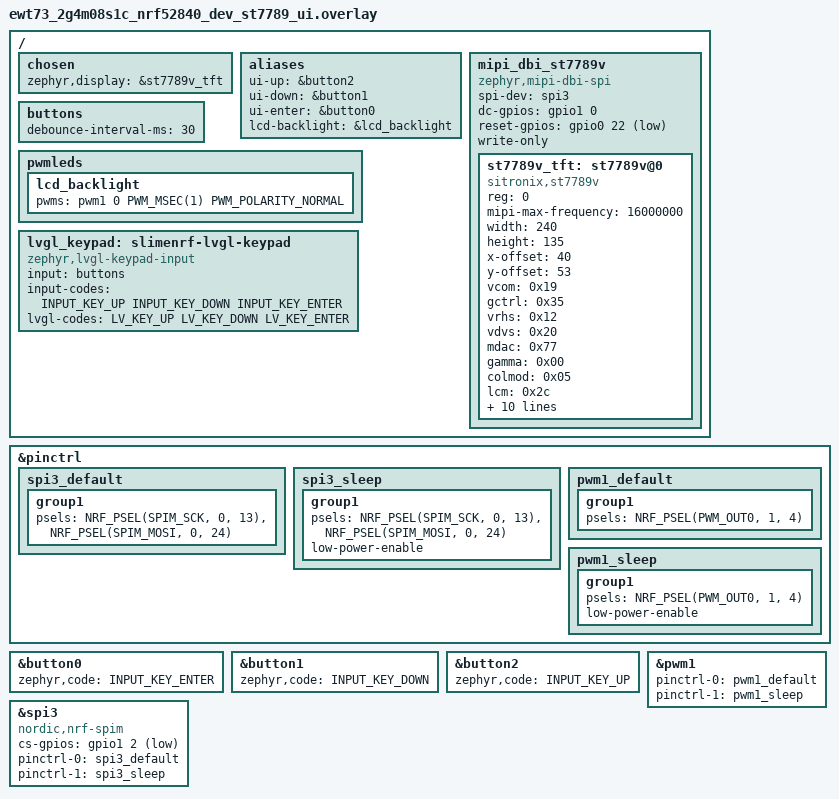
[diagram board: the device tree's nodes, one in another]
// Copyright (c) 2026
// SPDX-License-Identifier: Apache-2.0

#include <zephyr/dt-bindings/gpio/gpio.h>
#include <zephyr/dt-bindings/input/input-event-codes.h>
#include <zephyr/dt-bindings/lvgl/lvgl.h>
#include <zephyr/dt-bindings/mipi_dbi/mipi_dbi.h>

&pinctrl {
	spi3_default: spi3_default {
		group1 {
			psels = <NRF_PSEL(SPIM_SCK, 0, 13)>,
				<NRF_PSEL(SPIM_MOSI, 0, 24)>;
		};
	};

	spi3_sleep: spi3_sleep {
		group1 {
			psels = <NRF_PSEL(SPIM_SCK, 0, 13)>,
				<NRF_PSEL(SPIM_MOSI, 0, 24)>;
			low-power-enable;
		};
	};

	pwm1_default: pwm1_default {
		group1 {
			psels = <NRF_PSEL(PWM_OUT0, 1, 4)>;
		};
	};

	pwm1_sleep: pwm1_sleep {
		group1 {
			psels = <NRF_PSEL(PWM_OUT0, 1, 4)>;
			low-power-enable;
		};
	};
};

/ {
	chosen {
		zephyr,display = &st7789v_tft;
	};

	aliases {
		ui-up = &button2;
		ui-down = &button1;
		ui-enter = &button0;
		lcd-backlight = &lcd_backlight;
	};

	mipi_dbi_st7789v {
		compatible = "zephyr,mipi-dbi-spi";
		spi-dev = <&spi3>;
		dc-gpios = <&gpio1 0 GPIO_ACTIVE_HIGH>;
		reset-gpios = <&gpio0 22 GPIO_ACTIVE_LOW>;
		write-only;
		#address-cells = <1>;
		#size-cells = <0>;
		status = "okay";

		st7789v_tft: st7789v@0 {
			compatible = "sitronix,st7789v";
			reg = <0>;
			mipi-max-frequency = <16000000>;

			width = <240>;
			height = <135>;
			x-offset = <40>;
			y-offset = <53>;

			vcom = <0x19>;
			gctrl = <0x35>;
			vrhs = <0x12>;
			vdvs = <0x20>;
			mdac = <0x77>;
			gamma = <0x00>;
			colmod = <0x05>;
			lcm = <0x2c>;
			porch-param = [0c 0c 00 33 33];
			cmd2en-param = [5a 69 02 00];
			pwctrl1-param = [a4 a1];
			pvgam-param = [d0 04 0d 11 13 2b 3f 54 4c 18 0d 0b 1f 23];
			nvgam-param = [d0 04 0c 11 13 2c 3f 44 51 2f 1f 1f 20 23];
			ram-param = [00 f0];
			rgb-param = [40 02 14];
			mipi-mode = "MIPI_DBI_MODE_SPI_4WIRE";
			status = "okay";
		};
	};

	buttons: buttons {
		debounce-interval-ms = <30>;
	};

	pwmleds: pwmleds {
		lcd_backlight: lcd_backlight {
			pwms = <&pwm1 0 PWM_MSEC(1) PWM_POLARITY_NORMAL>;
		};
	};

	lvgl_keypad: slimenrf-lvgl-keypad {
		compatible = "zephyr,lvgl-keypad-input";
		input = <&buttons>;
		input-codes = <INPUT_KEY_UP INPUT_KEY_DOWN INPUT_KEY_ENTER>;
		lvgl-codes = <LV_KEY_UP LV_KEY_DOWN LV_KEY_ENTER>;
	};
};

&button0 {
	zephyr,code = <INPUT_KEY_ENTER>;
};

&button1 {
	zephyr,code = <INPUT_KEY_DOWN>;
};

&button2 {
	zephyr,code = <INPUT_KEY_UP>;
};

&pwm1 {
	status = "okay";
	pinctrl-0 = <&pwm1_default>;
	pinctrl-1 = <&pwm1_sleep>;
	pinctrl-names = "default", "sleep";
};

&spi3 {
	compatible = "nordic,nrf-spim";
	status = "okay";
	cs-gpios = <&gpio1 2 GPIO_ACTIVE_LOW>;
	pinctrl-0 = <&spi3_default>;
	pinctrl-1 = <&spi3_sleep>;
	pinctrl-names = "default", "sleep";
};
